# ATSAM4S16C device description
Architecture: CORTEX-M4; Family: SAM4; Series: SAM4S
Registers are 32-bit, read-write, no defined reset value unless marked. A register's access mark holds for its fields unless they carry their own. Offsets are from the block's base; [hi:lo] are bit positions; {n}, {i} and the like mark numbered series.

## PDC — Peripheral DMA Controller
0x00 PERIPH_RPR — Receive Pointer Register
  [31:0] RXPTR
0x04 PERIPH_RCR — Receive Counter Register
  [15:0] RXCTR
0x08 PERIPH_TPR — Transmit Pointer Register
  [31:0] TXPTR — Transmit Counter Register
0x0C PERIPH_TCR — Transmit Counter Register
  [15:0] TXCTR
0x10 PERIPH_RNPR — Receive Next Pointer Register
  [31:0] RXNPTR — Receive Next Pointer
0x14 PERIPH_RNCR — Receive Next Counter Register
  [15:0] RXNCTR — Receive Next Counter
0x18 PERIPH_TNPR — Transmit Next Pointer Register
  [31:0] TXNPTR — Transmit Next Pointer
0x1C PERIPH_TNCR — Transmit Next Counter Register
  [15:0] TXNCTR — Transmit Counter Next
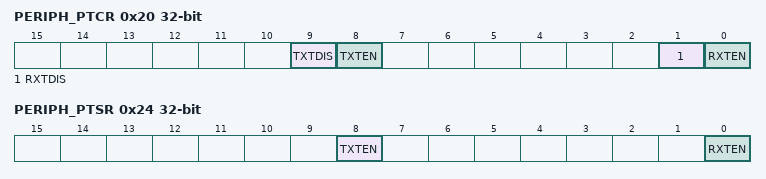
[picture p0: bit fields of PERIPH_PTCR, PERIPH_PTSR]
0x20 PERIPH_PTCR wo — Transfer Control Register
  [9] TXTDIS — Transmitter Transfer Disable
  [8] TXTEN — Transmitter Transfer Enable
  [1] RXTDIS — Receiver Transfer Disable
  [0] RXTEN — Receiver Transfer Enable
0x24 PERIPH_PTSR ro — Transfer Status Register
  [8] TXTEN — Transmitter Transfer Enable
  [0] RXTEN — Receiver Transfer Enable

## RSTC — Reset Controller
Instances: RSTC 0x400E1400
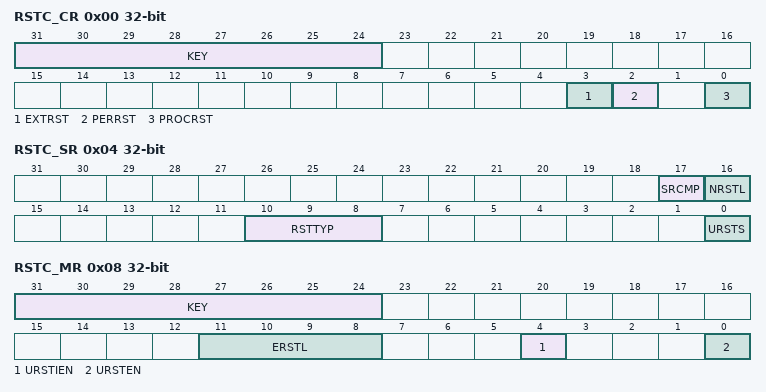
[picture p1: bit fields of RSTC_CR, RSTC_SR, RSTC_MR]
0x00 RSTC_CR wo — Control Register
  [31:24] KEY — System Reset Key
    165=PASSWD (Writing any other value in this field aborts the write operation.)
  [3] EXTRST — External Reset
  [2] PERRST — Peripheral Reset
  [0] PROCRST — Processor Reset
0x04 RSTC_SR ro — Status Register
  [17] SRCMP — Software Reset Command in Progress
  [16] NRSTL — NRST Pin Level
  [10:8] RSTTYP — Reset Type
    0=GENERAL_RST (First power-up reset); 1=BACKUP_RST (Return from Backup Mode); 2=WDT_RST (Watchdog fault occurred); 3=SOFT_RST (Processor reset required by the software); 4=USER_RST (NRST pin detected low)
  [0] URSTS — User Reset Status
0x08 RSTC_MR — Mode Register
  [31:24] KEY — Write Access Password
    165=PASSWD (Writing any other value in this field aborts the write operation.Always reads as 0.)
  [11:8] ERSTL — External Reset Length
  [4] URSTIEN — User Reset Interrupt Enable
  [0] URSTEN — User Reset Enable

## RTT — Real-time Timer
Instances: RTT 0x400E1430
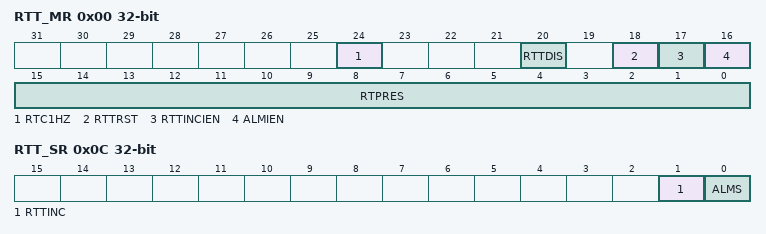
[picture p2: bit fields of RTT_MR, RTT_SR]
0x00 RTT_MR — Mode Register
  [24] RTC1HZ — Real-Time Clock 1Hz Clock Selection
  [20] RTTDIS — Real-time Timer Disable
  [18] RTTRST — Real-time Timer Restart
  [17] RTTINCIEN — Real-time Timer Increment Interrupt Enable
  [16] ALMIEN — Alarm Interrupt Enable
  [15:0] RTPRES — Real-time Timer Prescaler Value
0x04 RTT_AR — Alarm Register
  [31:0] ALMV — Alarm Value
0x08 RTT_VR ro — Value Register
  [31:0] CRTV — Current Real-time Value
0x0C RTT_SR ro — Status Register
  [1] RTTINC — Prescaler Roll-over Status (cleared on read)
  [0] ALMS — Real-time Alarm Status (cleared on read)

## SMC — Static Memory Controller
Instances: SMC 0x400E0000
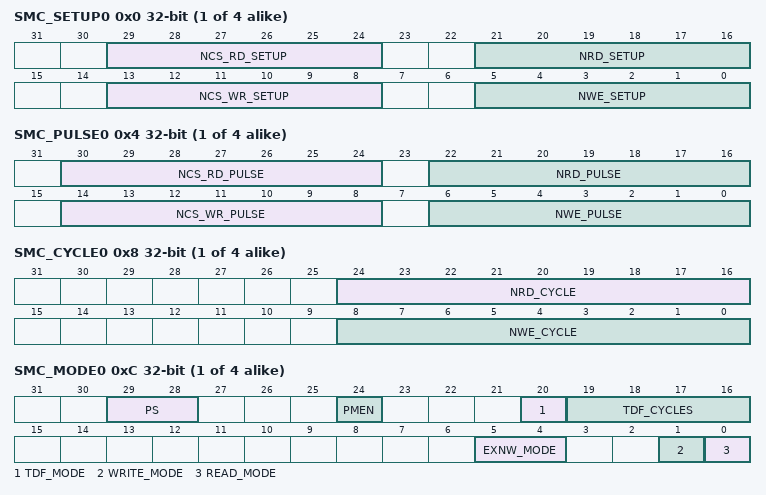
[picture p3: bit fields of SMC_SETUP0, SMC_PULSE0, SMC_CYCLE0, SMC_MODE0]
{0x0+0x10*i} SMC_SETUP{i} (i=0..3) — SMC Setup Register (CS_number = {i})
  [29:24] NCS_RD_SETUP — NCS Setup Length in READ Access
  [21:16] NRD_SETUP — NRD Setup Length
  [13:8] NCS_WR_SETUP — NCS Setup Length in WRITE Access
  [5:0] NWE_SETUP — NWE Setup Length
{0x4+0x10*i} SMC_PULSE{i} (i=0..3) — SMC Pulse Register (CS_number = {i})
  [30:24] NCS_RD_PULSE — NCS Pulse Length in READ Access
  [22:16] NRD_PULSE — NRD Pulse Length
  [14:8] NCS_WR_PULSE — NCS Pulse Length in WRITE Access
  [6:0] NWE_PULSE — NWE Pulse Length
{0x8+0x10*i} SMC_CYCLE{i} (i=0..3) — SMC Cycle Register (CS_number = {i})
  [24:16] NRD_CYCLE — Total Read Cycle Length
  [8:0] NWE_CYCLE — Total Write Cycle Length
{0xC+0x10*i} SMC_MODE{i} (i=0..3) — SMC MODE Register (CS_number = {i})
  [29:28] PS — Page Size
    0=_4_BYTE (4-byte page); 1=_8_BYTE (8-byte page); 2=_16_BYTE (16-byte page); 3=_32_BYTE (32-byte page)
  [24] PMEN — Page Mode Enabled
  [20] TDF_MODE — TDF Optimization
  [19:16] TDF_CYCLES — Data Float Time
  [5:4] EXNW_MODE — NWAIT Mode
    0=DISABLED; 2=FROZEN (Frozen Mode); 3=READY (Ready Mode)
  [1] WRITE_MODE
  [0] READ_MODE
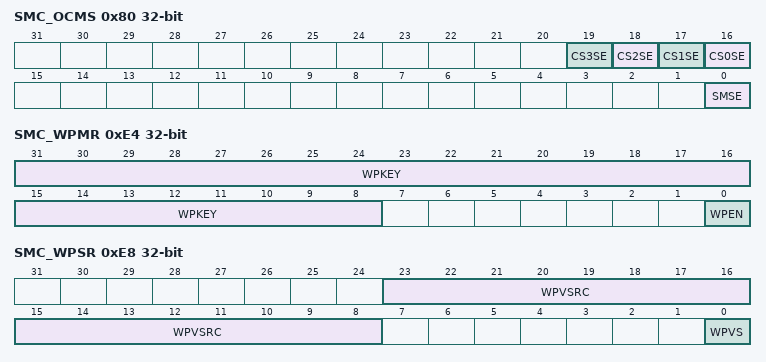
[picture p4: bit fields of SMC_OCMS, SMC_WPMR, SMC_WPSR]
0x80 SMC_OCMS — SMC OCMS MODE Register
  [n+16] CS{n}SE (n=0..3) — Chip Select (x = 0 to 3) Scrambling Enable
  [0] SMSE — Static Memory Controller Scrambling Enable
0x84 SMC_KEY1 wo — SMC OCMS KEY1 Register
  [31:0] KEY1 — Off Chip Memory Scrambling (OCMS) Key Part 1
0x88 SMC_KEY2 wo — SMC OCMS KEY2 Register
  [31:0] KEY2 — Off Chip Memory Scrambling (OCMS) Key Part 2
0xE4 SMC_WPMR — SMC Write Protection Mode Register
  [31:8] WPKEY — Write Protection Key
    0x534D43=PASSWD (Writing any other value in this field aborts the write operation of the WPEN bit. Always reads as 0.)
  [0] WPEN — Write Protect Enable
0xE8 SMC_WPSR ro — SMC Write Protection Status Register
  [23:8] WPVSRC — Write Protection Violation Source
  [0] WPVS — Write Protection Violation Status

## Notices in the file
SAM Software Package License
Copyright (c) %copyright_year%, Atmel Corporation
All rights reserved.
Redistribution and use in source and binary forms, with or without
modification, are permitted provided that the following condition is met:
- Redistributions of source code must retain the above copyright notice,
this list of conditions and the disclaimer below.
Atmel's name may not be used to endorse or promote products derived from
this software without specific prior written permission.
DISCLAIMER:  THIS SOFTWARE IS PROVIDED BY ATMEL "AS IS" AND ANY EXPRESS OR
IMPLIED WARRANTIES, INCLUDING, BUT NOT LIMITED TO, THE IMPLIED WARRANTIES OF
MERCHANTABILITY, FITNESS FOR A PARTICULAR PURPOSE AND NON-INFRINGEMENT ARE
DISCLAIMED. IN NO EVENT SHALL ATMEL BE LIABLE FOR ANY DIRECT, INDIRECT,
INCIDENTAL, SPECIAL, EXEMPLARY, OR CONSEQUENTIAL DAMAGES (INCLUDING, BUT NOT
LIMITED TO, PROCUREMENT OF SUBSTITUTE GOODS OR SERVICES; LOSS OF USE, DATA,
OR PROFITS; OR BUSINESS INTERRUPTION) HOWEVER CAUSED AND ON ANY THEORY OF
LIABILITY, WHETHER IN CONTRACT, STRICT LIABILITY, OR TORT (INCLUDING
NEGLIGENCE OR OTHERWISE) ARISING IN ANY WAY OUT OF THE USE OF THIS SOFTWARE,
EVEN IF ADVISED OF THE POSSIBILITY OF SUCH DAMAGE.
